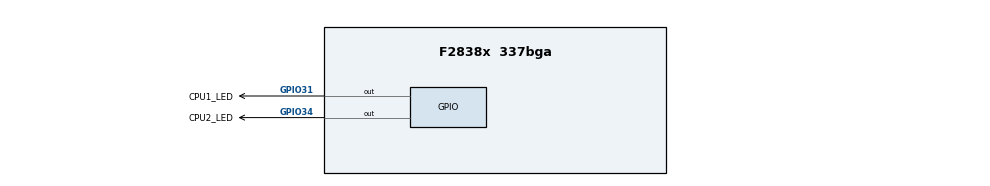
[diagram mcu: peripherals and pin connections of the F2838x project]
/**
 * @cliArgs --device "F2838x" --package "337bga" --part "F2838x_337bga" --context "CPU1" --product "C2000WARE@4.02.00.00"
 * @versions {"tool":"1.13.0+2553"}
 */

/**
 * Import the modules used in this configuration.
 */
const gpio  = scripting.addModule("/driverlib/gpio.js", {}, false);
const gpio1 = gpio.addInstance();
const gpio2 = gpio.addInstance();
const ipc   = scripting.addModule("/driverlib/ipc.js");

/**
 * Write custom configuration values to the imported modules.
 */
gpio1.direction       = "GPIO_DIR_MODE_OUT";
gpio1.$name           = "CPU1_LED";
gpio1.gpioPin.$assign = "GPIO31";

gpio2.direction       = "GPIO_DIR_MODE_OUT";
gpio2.masterCore      = "GPIO_CORE_CPU2";
gpio2.$name           = "CPU2_LED";
gpio2.gpioPin.$assign = "GPIO34";

ipc.ipcRegisterFlag = ["IPC_FLAG31"];
ipc.flagHandler31   = "IPC_SYNC";
